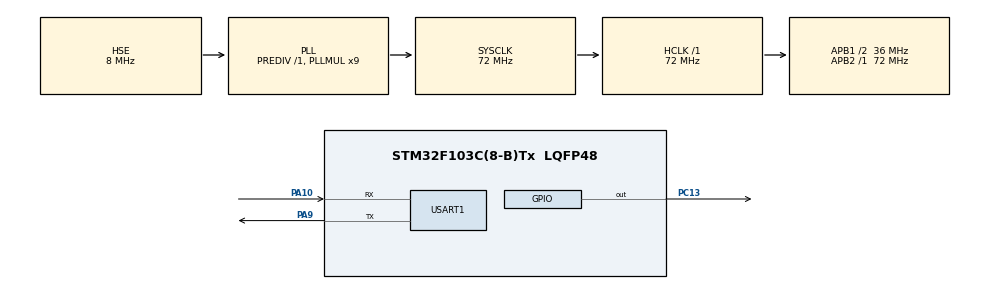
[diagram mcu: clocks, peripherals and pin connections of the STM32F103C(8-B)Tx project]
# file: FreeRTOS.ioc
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Mcu.Family=STM32F1
Mcu.Name=STM32F103C(8-B)Tx
Mcu.Package=LQFP48
NVIC.PriorityGroup=NVIC_PRIORITYGROUP_4
NVIC.TIM3_IRQn=true\:6\:0\:true\:false\:true\:true\:true\:true
NVIC.TIM4_IRQn=true\:15\:0\:false\:false\:true\:false\:true\:true
NVIC.TimeBase=TIM4_IRQn
NVIC.TimeBaseIP=TIM4
PA10.Mode=Asynchronous
PA10.Signal=USART1_RX
PA13.Mode=Serial_Wire
PA13.Signal=SYS_JTMS-SWDIO
PA14.Mode=Serial_Wire
PA14.Signal=SYS_JTCK-SWCLK
PA9.Mode=Asynchronous
PA9.Signal=USART1_TX
PC13-TAMPER-RTC.PinState=GPIO_PIN_SET
PC13-TAMPER-RTC.Signal=GPIO_Output
PC14-OSC32_IN.Mode=LSE-External-Oscillator
PC14-OSC32_IN.Signal=RCC_OSC32_IN
PC15-OSC32_OUT.Mode=LSE-External-Oscillator
PC15-OSC32_OUT.Signal=RCC_OSC32_OUT
PD0-OSC_IN.Mode=HSE-External-Oscillator
PD0-OSC_IN.Signal=RCC_OSC_IN
PD1-OSC_OUT.Mode=HSE-External-Oscillator
PD1-OSC_OUT.Signal=RCC_OSC_OUT
ProjectManager.HeapSize=0x200
ProjectManager.StackSize=0x400
ProjectManager.TargetToolchain=MDK-ARM V5.32
RCC.AHBFreq_Value=72000000
RCC.APB1CLKDivider=RCC_HCLK_DIV2
RCC.APB1Freq_Value=36000000
RCC.APB1TimFreq_Value=72000000
RCC.APB2Freq_Value=72000000
RCC.APB2TimFreq_Value=72000000
RCC.HCLKFreq_Value=72000000
RCC.PLLMUL=RCC_PLL_MUL9
RCC.PLLSourceVirtual=RCC_PLLSOURCE_HSE
RCC.SYSCLKFreq_VALUE=72000000
RCC.SYSCLKSource=RCC_SYSCLKSOURCE_PLLCLK
RCC.USBFreq_Value=72000000
TIM3.Period=9
TIM3.Prescaler=71
USART1.VirtualMode=VM_ASYNC
VP_SYS_VS_tim4.Mode=TIM4
VP_TIM3_VS_ClockSourceINT.Mode=Internal
board=custom

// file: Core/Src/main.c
/* USER CODE BEGIN Header */
/**
  ******************************************************************************
  * @file           : main.c
  * @brief          : Main program body
  ******************************************************************************
  * @attention
  *
  * Copyright (c) 2025 STMicroelectronics.
  * All rights reserved.
  *
  * This software is licensed under terms that can be found in the LICENSE file
  * in the root directory of this software component.
  * If no LICENSE file comes with this software, it is provided AS-IS.
  *
  ******************************************************************************
  */
/* USER CODE END Header */
#include "main.h"
#include "tim.h"
#include "usart.h"
#include "gpio.h"

/* USER CODE BEGIN Includes */
#include "FreeRTOS.h"
#include "task.h"
/* USER CODE END Includes */

void SystemClock_Config(void);

/* USER CODE BEGIN 0 */

//start task
void Start_Task(void *pvParameters);
#define START_TASK_STACK_DEPTH 128
#define START_TASK_PRIORITY 1
TaskHandle_t start_task_handler;

//led toggle task
void LED_Toggle_Task(void *pvParameters);
#define LED_TOGGLE_TASK_STACK_DEPTH 128
#define LED_TOGGLE_TASK_PRIORITY 4
TaskHandle_t led_toggle_task_handler;

//runtime stats task
void Runtime_Stats_Task(void *pvParameters);
#define RUNTIME_STATS_TASK_STACK_DEPTH 128
#define RUNTIME_STATS_TASK_PRIORITY 2
TaskHandle_t runtime_stats_task_handler;

void Start_Task(void *pvParameters)
{
  taskENTER_CRITICAL();
  xTaskCreate((TaskFunction_t)LED_Toggle_Task,
              (char *)"LED_Toggle_Task",
              (configSTACK_DEPTH_TYPE)LED_TOGGLE_TASK_STACK_DEPTH,
              (void *)NULL,
              (UBaseType_t)LED_TOGGLE_TASK_PRIORITY,
              (TaskHandle_t *)&led_toggle_task_handler);
  xTaskCreate((TaskFunction_t)Runtime_Stats_Task,
              (char *)"Runtime_Stats_Task",
              (configSTACK_DEPTH_TYPE)RUNTIME_STATS_TASK_STACK_DEPTH,
              (void *)NULL,
              (UBaseType_t)RUNTIME_STATS_TASK_PRIORITY,
              (TaskHandle_t *)&runtime_stats_task_handler);
  vTaskDelete(NULL);
  taskEXIT_CRITICAL();
}

void LED_Toggle_Task(void *pvParameters)
{
  while (1)
  {
    HAL_GPIO_TogglePin(GPIOC, GPIO_PIN_13);
    vTaskDelay(1000);
  }
}

void Runtime_Stats_Task(void *pvParameters)
{
  char runtime_stats_buffer[128];
  while (1)
  {
    taskENTER_CRITICAL();
    vTaskGetRunTimeStats(runtime_stats_buffer);
    printf("%s\r\n", runtime_stats_buffer);
    taskEXIT_CRITICAL();
    vTaskDelay(2000);
  }
}

void FreeRTOS_Start(void)
{
  xTaskCreate((TaskFunction_t)Start_Task,
              (char *)"Start_Task",
              (configSTACK_DEPTH_TYPE)START_TASK_STACK_DEPTH,
              (void *)NULL,
              (UBaseType_t)START_TASK_PRIORITY,
              (TaskHandle_t *)&start_task_handler);
  vTaskStartScheduler();
}

/* USER CODE END 0 */

int main(void)
{

  /* MCU Configuration--------------------------------------------------------*/

  /* Reset of all peripherals, Initializes the Flash interface and the Systick. */
  HAL_Init();

  /* Configure the system clock */
  SystemClock_Config();

  /* Initialize all configured peripherals */
  MX_GPIO_Init();
  MX_TIM3_Init();
  MX_USART1_UART_Init();
  /* USER CODE BEGIN 2 */
  HAL_TIM_Base_Start_IT(&htim3);
  FreeRTOS_Start();
  /* USER CODE END 2 */

  /* Infinite loop */
  while (1)
  {

  }
}

void SystemClock_Config(void)
{
  RCC_OscInitTypeDef RCC_OscInitStruct = {0};
  RCC_ClkInitTypeDef RCC_ClkInitStruct = {0};

  /** Initializes the RCC Oscillators according to the specified parameters
  * in the RCC_OscInitTypeDef structure.
  */
  RCC_OscInitStruct.OscillatorType = RCC_OSCILLATORTYPE_HSE;
  RCC_OscInitStruct.HSEState = RCC_HSE_ON;
  RCC_OscInitStruct.HSEPredivValue = RCC_HSE_PREDIV_DIV1;
  RCC_OscInitStruct.HSIState = RCC_HSI_ON;
  RCC_OscInitStruct.PLL.PLLState = RCC_PLL_ON;
  RCC_OscInitStruct.PLL.PLLSource = RCC_PLLSOURCE_HSE;
  RCC_OscInitStruct.PLL.PLLMUL = RCC_PLL_MUL9;
  if (HAL_RCC_OscConfig(&RCC_OscInitStruct) != HAL_OK)
  {
    Error_Handler();
  }

  /** Initializes the CPU, AHB and APB buses clocks
  */
  RCC_ClkInitStruct.ClockType = RCC_CLOCKTYPE_HCLK|RCC_CLOCKTYPE_SYSCLK
                              |RCC_CLOCKTYPE_PCLK1|RCC_CLOCKTYPE_PCLK2;
  RCC_ClkInitStruct.SYSCLKSource = RCC_SYSCLKSOURCE_PLLCLK;
  RCC_ClkInitStruct.AHBCLKDivider = RCC_SYSCLK_DIV1;
  RCC_ClkInitStruct.APB1CLKDivider = RCC_HCLK_DIV2;
  RCC_ClkInitStruct.APB2CLKDivider = RCC_HCLK_DIV1;

  if (HAL_RCC_ClockConfig(&RCC_ClkInitStruct, FLASH_LATENCY_2) != HAL_OK)
  {
    Error_Handler();
  }
}

/* USER CODE BEGIN 4 */
volatile unsigned long ulHighFrequencyTimerTicks;
/* USER CODE END 4 */

void HAL_TIM_PeriodElapsedCallback(TIM_HandleTypeDef *htim)
{
  /* USER CODE BEGIN Callback 0 */
  if (htim->Instance == TIM3)
  {
    ulHighFrequencyTimerTicks++;
  }

  /* USER CODE END Callback 0 */
  if (htim->Instance == TIM4)
  {
    HAL_IncTick();
  }
}

void Error_Handler(void)
{
  __disable_irq();
  while (1)
  {
  }
}
